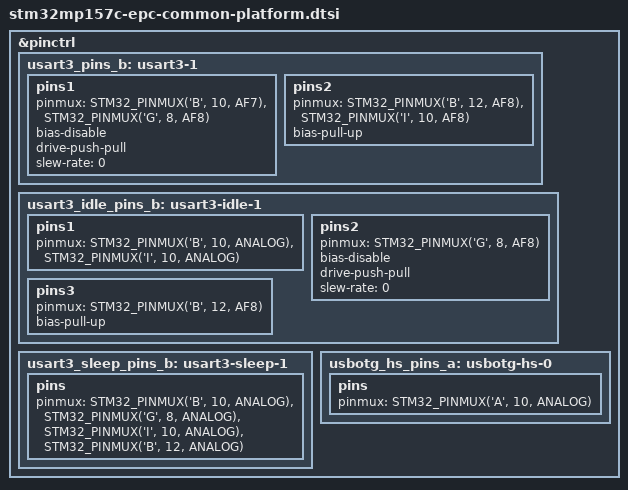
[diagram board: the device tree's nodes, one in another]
#include <dt-bindings/pinctrl/stm32-pinfunc.h>

&pinctrl {
	usart3_pins_b: usart3-1 {
		pins1 {
			pinmux = <STM32_PINMUX('B', 10, AF7)>, /* USART3_TX */
				 <STM32_PINMUX('G', 8, AF8)>; /* USART3_RTS */
			bias-disable;
			drive-push-pull;
			slew-rate = <0>;
		};
		pins2 {
			pinmux = <STM32_PINMUX('B', 12, AF8)>, /* USART3_RX */
				 <STM32_PINMUX('I', 10, AF8)>; /* USART3_CTS_NSS */
			bias-pull-up;
		};
	};

	usart3_idle_pins_b: usart3-idle-1 {
		pins1 {
			pinmux = <STM32_PINMUX('B', 10, ANALOG)>, /* USART3_TX */
				 <STM32_PINMUX('I', 10, ANALOG)>; /* USART3_CTS_NSS */
		};
		pins2 {
			pinmux = <STM32_PINMUX('G', 8, AF8)>; /* USART3_RTS */
			bias-disable;
			drive-push-pull;
			slew-rate = <0>;
		};
		pins3 {
			pinmux = <STM32_PINMUX('B', 12, AF8)>; /* USART3_RX */
			bias-pull-up;
		};
	};

	usart3_sleep_pins_b: usart3-sleep-1 {
		pins {
			pinmux = <STM32_PINMUX('B', 10, ANALOG)>, /* USART3_TX */
				 <STM32_PINMUX('G', 8, ANALOG)>, /* USART3_RTS */
				 <STM32_PINMUX('I', 10, ANALOG)>, /* USART3_CTS_NSS */
				 <STM32_PINMUX('B', 12, ANALOG)>; /* USART3_RX */
		};
	};

	usbotg_hs_pins_a: usbotg-hs-0 {
		pins {
			pinmux = <STM32_PINMUX('A', 10, ANALOG)>; /* OTG_ID */
		};
	};
};
